# ipro7 register map
Vendor: intelpro; Series: BTBLE
CPU: ipro7, little endian
Registers are 32-bit, read-write, reset 0x0 unless marked. A register's access mark holds for its fields unless they carry their own. Offsets are from the block's base; [hi:lo] are bit positions; {n}, {i} and the like mark numbered series; <NAME> marks a mode.

## AUD
Base 0x30017000
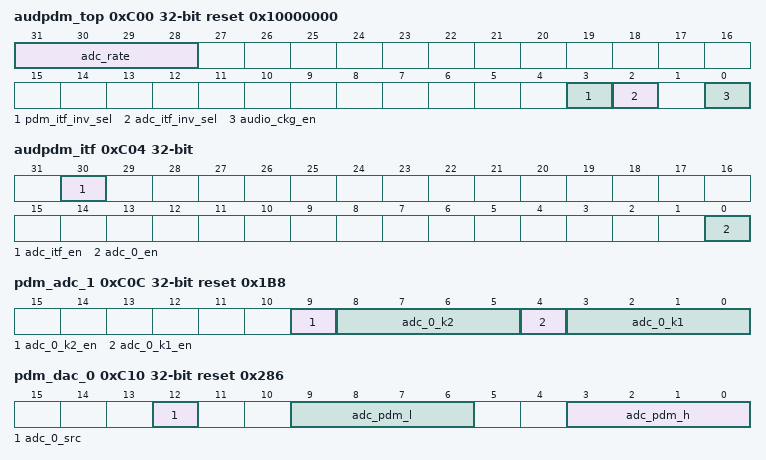
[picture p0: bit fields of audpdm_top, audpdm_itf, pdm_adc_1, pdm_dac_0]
0xC00 audpdm_top reset 0x10000000
  [31:28] adc_rate — adc fs 0:8kHz,1:16kHz, 2:24kHz(22.05k), 3:32kHz, 4:48kHz(44.1k), 5:96kHz, 6:reserved, 7:manual, 8:padc 128kHz, 9:padc 256kHz, 10:padc 512kHz
  [3] pdm_itf_inv_sel — 1:invert clk_pdm_inf
  [2] adc_itf_inv_sel — 1:invert clk_adc_itf
  [0] audio_ckg_en — 1:enable audio clock generator
0xC04 audpdm_itf
  [30] adc_itf_en — 1:enable adc to audio dma interface
  [0] adc_0_en — 1:enable adc ch0
0xC08 pdm_adc_0
  [0] adc_0_fir_mode — adc fir mode
0xC0C pdm_adc_1 reset 0x1B8
  [9] adc_0_k2_en — adc ch0 hpf parameter k2 enable
  [8:5] adc_0_k2 — adc ch0 hpf parameter k2
  [4] adc_0_k1_en — adc ch0 hpf parameter k1 enable
  [3:0] adc_0_k1 — adc ch0 hpf parameter k1
0xC10 pdm_dac_0 reset 0x286
  [12] adc_0_src — 0:adc, 1:pdm
  [9:6] adc_pdm_l — pdm low value
  [3:0] adc_pdm_h — pdm high value
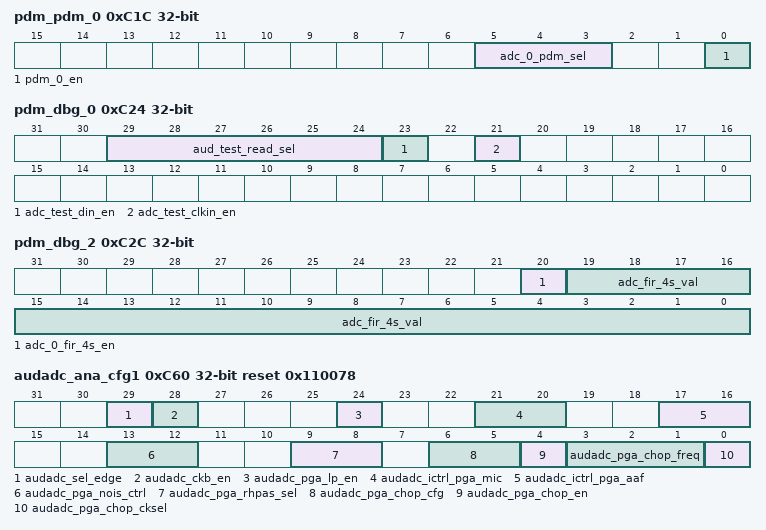
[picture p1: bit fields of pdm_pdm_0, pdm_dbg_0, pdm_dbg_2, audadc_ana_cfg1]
0xC1C pdm_pdm_0
  [5:3] adc_0_pdm_sel — adc ch0 source select: 0:pdm_0_l, 1:pdm_0_r, 2:pdm_1_l, 3:pdm_1_r, 4:pdm_2_l, 5:pdm_2_r
  [0] pdm_0_en — 1:enable pdm_0
0xC20 pdm_rsvd0 reset 0xFFFF
0xC24 pdm_dbg_0
  [29:24] aud_test_read_sel — select aud_test_read(0x28) test point
  [23] adc_test_din_en — 1:enable adc test data input from GPIO
  [21] adc_test_clkin_en — 1:enable adc test clcok input from GPIO
0xC28 pdm_dbg_1 reset not defined
  [31:0] aud_test_read ro — audio test read value
0xC2C pdm_dbg_2
  [20] adc_0_fir_4s_en — 1:force adc ch0 fir output
  [19:0] adc_fir_4s_val — force value of adc fir output
0xC30 pdm_dbg_3
0xC34 pdm_dbg_4
0xC38 pdm_adc_s0
  [8:0] adc_s0_volume — volume s9.1, -95.5dB ~ +18dB in 0.5dB step
0xC3C pdm_adc_s1
0xC40 pdm_adc_s2
0xC60 audadc_ana_cfg1 reset 0x110078
  [29] audadc_sel_edge — ADC output data clock edge 0 = falling edge sent, rising edge recieve 1 = rising edge sent, falling edge recieve
  [28] audadc_ckb_en — AUDADC clock phase control 0 = 0° 1 = 180°
  [24] audadc_pga_lp_en — PGA lowpower funciton reversed, not realized in circuit
  [21:20] audadc_ictrl_pga_mic — PGA_OPMIC bias current control 00 = 4uA 01 = 5uA 10 = 6uA 11 = 7uA
  [17:16] audadc_ictrl_pga_aaf — PGA_OPAAF bias current control 00 = 4uA 01 = 5uA 10 = 6uA 11 = 7uA
  [13:12] audadc_pga_nois_ctrl — PGA noise control when configured to single-ended not used
  [9:8] audadc_pga_rhpas_sel — PGA high pass filter R control when configured to AC-coupled mode 00 = 480kΩ 01 = 320kΩ 10 = 160kΩ 11 = 4kΩ, fast startup
  [6:5] audadc_pga_chop_cfg — control chopper for opmic&opaaf 00 = opmic off & opaaf off 01 = opmic off & opaaf on 10 = opmic on & opaaf off 11 = opmic on & opaaf on
  [4] audadc_pga_chop_en — PGA chopper control 0 = disable 1 = enable
  [3:1] audadc_pga_chop_freq — PGA chopper frequency control @Fs=2048k 000 = 8k 001 = 16k 010 = 32k 011 = 64k 100 = 128k 101 = 256k 110 = 512k 111 = 1024k
  [0] audadc_pga_chop_cksel — PGA chopper clock source selection 0 = adc clock 1 = synchronized clock from SDM not used
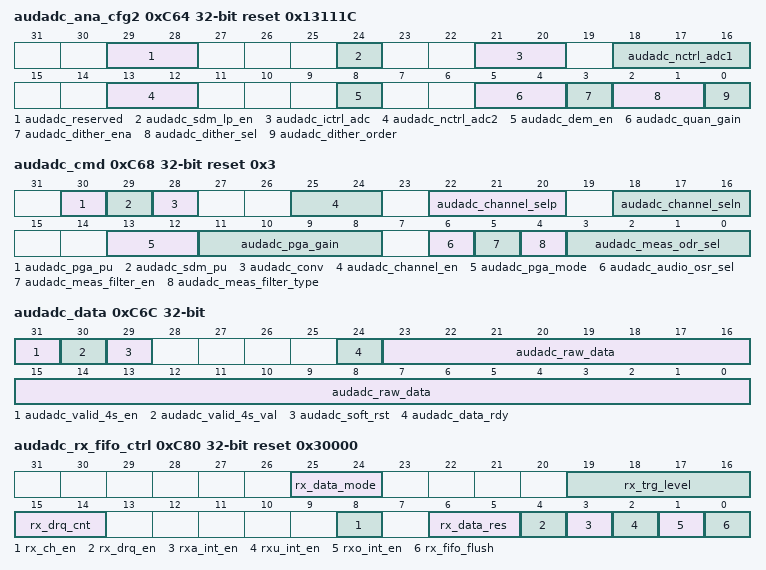
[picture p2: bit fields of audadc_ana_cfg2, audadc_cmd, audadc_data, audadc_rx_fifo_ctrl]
0xC64 audadc_ana_cfg2 reset 0x13111C
  [29:28] audadc_reserved
  [24] audadc_sdm_lp_en — SDM lowpower funciton 0 = disable 1 = enable, 0.6 of disable
  [21:20] audadc_ictrl_adc — SDM bias current control 00 = 4uA 01 = 5uA 10 = 6uA 11 = 7uA
  [18:16] audadc_nctrl_adc1 — op number control for first integrator in SDM 000 = 1(12uA) 001 = 2(24uA) 010 = 3(36uA) 011 = 4(48uA) 100 = 5(60uA) 101 = 5(60uA) 110 = 5(60uA) 111 = 5(60uA)
  [13:12] audadc_nctrl_adc2 — op number control for second integrator in SDM 00 = 1(12uA) 01 = 2(24uA) 10 = 3(36uA) 11 = 3(36uA)
  [8] audadc_dem_en — dem function control 0 = disable 1 = enable
  [5:4] audadc_quan_gain — quantizer gain control for SDM 00 = Vref/14 01 = Vref/12 10 = Vref/10 11 = Vref/8
  [3] audadc_dither_ena — dither control 0 = disable 1 = enable
  [2:1] audadc_dither_sel — dither level control for SDM 00 = 0 01 = LSB*1/15 10 = LSB*2/15 11 = LSB*3/15
  [0] audadc_dither_order — dither order control for SDM 0 = 0 order 1 = 1 order
0xC68 audadc_cmd reset 0x3
  [30] audadc_pga_pu — PGA related circuit enable 0 = disable 1 = enable
  [29] audadc_sdm_pu — SDM related circuit enable 0 = disable 1 = enable
  [28] audadc_conv — SDM conversion start singal 0 = remain resetting status 1 = start conversion both analog intetrator and measuring digitial decimation filter will be reset when audadc_conv configured to low. Measuring digital decimation filter need to reset to same initial condition because it's feedback configuration for FIR. Audio filter dont need this resetting.
  [25:24] audadc_channel_en — channel mux switch enable or disable MSB controls Positive channel, LSB controls Negative channel 0 = disable, look into each channel will see high impedance 1 = enable, one of eight channel will be choose
  [22:20] audadc_channel_selp — Positive channel selection, connected to PGA positive terminal 000 = AIN0 001 = AIN1 010 = AIN2 011 = AIN3 100 = AIN4 101 = AIN5 110 = AIN6 111 = AIN7
  [18:16] audadc_channel_seln — Negative channel selection, connected to PGA negative terminal 000 = AIN0 001 = AIN1 010 = AIN2 011 = AIN3 100 = AIN4 101 = AIN5 110 = AIN6 111 = AIN7
  [13:12] audadc_pga_mode — PGA mode configuration 00: AC-Coupled & differential-ended, Audio application 01: AC-Coupled & single-ended, Audio application 10: DC-Coupled & differential-ended, Measuring application 11: DC-Coupled & single-ended, Measuring application(may not used)
  [11:8] audadc_pga_gain — PGA Gain control 0000 = 6dB 0001 = 6dB 0010 = 6dB 0011 = 9dB 0100 = 12dB 0101 = 15dB 0110 = 18dB 0111 = 21dB 1000 = 24dB 1001 = 27dB 1010 = 30dB 1011 = 33dB 1100 = 36dB 1101 = 39dB 1110 = 42dB 1111 = 42dB
  [6] audadc_audio_osr_sel — audio osr configuration 0 = 128 1 = 64
  [5] audadc_meas_filter_en — measuring mode enable, measuring filter is on when set to high 0 = disable 1 = enable
  [4] audadc_meas_filter_type — digital dicimation filter selection when in measuring mode 0 = SINC3 1 = Low-Latency
  [3:0] audadc_meas_odr_sel — audadc ouput data rate selection when configured to measuring mode 0000 = 2.5SPS 0001 = 5SPS 0010 = 10SPS 0011 = 20SPS 0100 = 25SPS 0101 = 50SPS 0110 = 100SPS 0111 = 200SPS 1000 = 400SPS 1001 = 800SPS 1010 = 1000SPS 1011 = 2000SPS 1100 = 4000SPS 1101 = 4000SPS 1110 = 4000SPS 1111 = 4000SPS
0xC6C audadc_data (reset mask 0xFE000000)
  [31] audadc_valid_4s_en
  [30] audadc_valid_4s_val
  [29] audadc_soft_rst
  [24] audadc_data_rdy ro — audadc data ready indicator when measuring mode selected, auto reset to 0 after read 0 = not ready 1 = ready
  [23:0] audadc_raw_data ro — audadc output 16bit data, 2's
0xC80 audadc_rx_fifo_ctrl reset 0x30000
  [25:24] rx_data_mode — RX_FIFO_DATOUT_MODE. RX FIFO DATA Output Mode (Mode 0, 1, 2, 3) Mode 0: Valid data's MSB is at [31] of RX_FIFO register Mode 1: Valid data's MSB is at [23] of RX_FIFO register Mode 2: Valid data's MSB is at [19] of RX_FIFO register Mode 3: Valid data's MSB is at [15] of RX_FIFO register Note: Expanding ‘0’ at LSB of RX FIFO register (data invalid region) Expanding sign bit at MSB of RX FIFO register (data invalid region) For 24-bit received audio sample resolution: Mode 0: RXDATA[31:0] = {FIFO_O[23:0], 8’h0} Mode 1: RXDATA[31:0] = {8{FIFO_O[23]}, FIFO_O[23:0]} Mode 2: RXDATA[31:0] = {12{FIFO_O[23]}, FIFO_O[23:4]} Mode 3: RXDATA[31:0] = {16{FIFO_O[23]}, FIFO_O[23:8]} For 20-bit received audio sample resolution: Mode 0: RXDATA[31:0] = {FIFO_O[23:4], 12’h0} Mode 1: RXDATA[31:0] = {8{FIFO_O[23]}, FIFO_O[23:4], 4’h0} Mode 2: RXDATA[31:0] = {12{FIFO_O[23]}, FIFO_O[23:4]} Mode 3: RXDATA[31:0] = {16{FIFO_O[23]}, FIFO_O[23:8]} For 16-bit received audio sample resolution: Mode 0: RXDATA[31:0] = {FIFO_O[23:8], 16’h0} Mode 1: RXDATA[31:0] = {8{FIFO_O[23]}, FIFO_O[23:8], 8’h0} Mode 2: RXDATA[31:0] = {12{FIFO_O[23]}, FIFO_O[23:8], 4'h0} Mode 3: RXDATA[31:0] = {16{FIFO_O[23]}, FIFO_O[23:8]}
  [19:16] rx_trg_level — RX_FIFO_TRG_LEVEL. RX FIFO Trigger Level (RXTL[3:0]) Interrupt and DMA request trigger level for RX FIFO Data Available condition IRQ/DRQ Generated when WLEVEL > RXTL[3:0] Notes: WLEVEL represents the number of valid samples in the RX FIFO
  [15:14] rx_drq_cnt — RX_DRQ_CLR_CNT. When RX FIFO available data less than or equal N, DRQ Request will be de-asserted. N is defined here: 00: IRQ/DRQ de-asserted when WLEVEL <= RXTL[3:0] 01: IRQ/DRQ de-asserted when WLEVEL < 1 10: IRQ/DRQ de-asserted when WLEVEL < 2 11: IRQ/DRQ de-asserted when WLEVEL < 4 WLEVEL represents the number of valid samples in the RX FIFO
  [8] rx_ch_en — RX_FIFO_DATIN_SRC. RX FIFO Data Input Source Select. 0: Disable 1: Enable Bit8: ADC1 data
  [6:5] rx_data_res — RX_SAMPLE_BITS. Receiving Audio Sample Resolution 0: 16 bits 1: 20 bits 2: 24 bits 3: Reserved
  [4] rx_drq_en — ADC_DRQ_EN. ADC FIFO Data Available DRQ Enable. 0: Disable 1: Enable
  [3] rxa_int_en — ADC_IRQ_EN. ADC FIFO Data Available IRQ Enable. 0: Disable 1: Enable
  [2] rxu_int_en — ADC_UNDERRUN_IRQ_EN. ADC FIFO Under Run IRQ Enable 0: Disable 1: Enable
  [1] rxo_int_en — ADC_OVERRUN_IRQ_EN. ADC FIFO Over Run IRQ Enable 0: Disable 1: Enable
  [0] rx_fifo_flush — ADC_FIFO_FLUSH. ADC FIFO Flush. Write ‘1’ to flush TX FIFO, self clear to ‘0’.
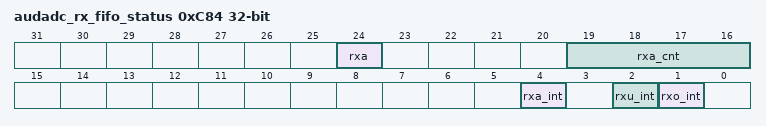
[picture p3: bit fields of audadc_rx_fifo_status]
0xC84 audadc_rx_fifo_status (reset mask 0xFEF0FFE9)
  [24] rxa ro — RXA. RX FIFO Available 0: No available data in RX FIFO 1: More than one sample in RX FIFO (>= 1 word)
  [19:16] rxa_cnt ro — RXA_CNT. RX FIFO Available Sample Word Counter
  [4] rxa_int ro — RXA_INT. RX FIFO Data Available Pending Interrupt 0: No Pending IRQ 1: Data Available Pending IRQ Automatic clear if interrupt condition fails.
  [2] rxu_int ro — RXU_INT. RX FIFO Underrun Pending Interrupt 0: No Pending IRQ 1: FIFO Underrun Pending IRQ Write ‘1’ to clear this interrupt
  [1] rxo_int ro — RXO_INT. RX FIFO Overrun Pending Interrupt 0: No Pending IRQ 1: FIFO Overrun Pending IRQ Write ‘1’ to clear this interrupt
0xC88 audadc_rx_fifo_data reset not defined
  [31:0] rx_data ro — RX_DATA. RX Sample Host can get one sample by reading this register. The left channel sample data is first and then the right channel sample.
